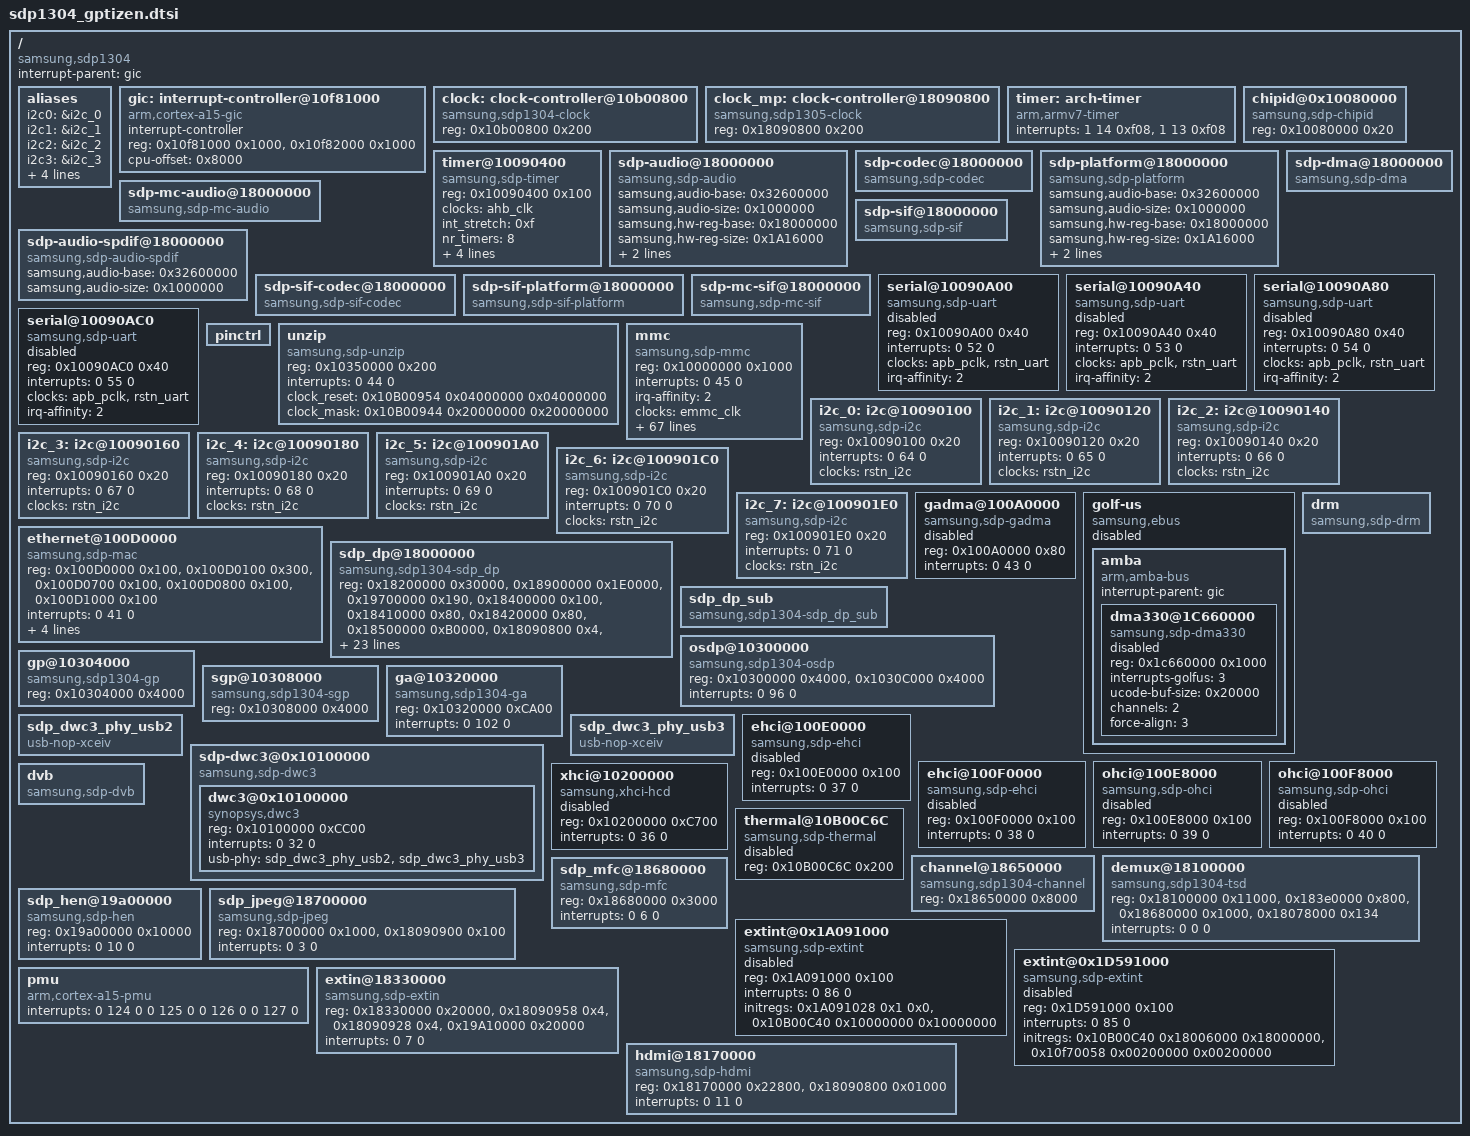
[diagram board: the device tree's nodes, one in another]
/*
 * Copyright (C) 2013 Samsung Electronics Co.Ltd
 *
 * This program is free software; you can redistribute it and/or modify
 * it under the terms of the GNU General Public License version 2 as
 * published by the Free Software Foundation.
 */

#include "sdp.dtsi"
#include "sdp1304-clocks.dtsi"
#include "sdp1304-pinctrl.dtsi"

/ {
	compatible = "samsung,sdp1304";

	interrupt-parent = <&gic>;

	aliases {
		i2c0 = &i2c_0;
		i2c1 = &i2c_1;
		i2c2 = &i2c_2;
		i2c3 = &i2c_3;
		i2c4 = &i2c_4;
		i2c5 = &i2c_5;
		i2c6 = &i2c_6;
		i2c7 = &i2c_7;
	};

	gic: interrupt-controller@10f81000 {
		compatible = "arm,cortex-a15-gic";
		interrupt-controller;
		#interrupt-cells = <3>;
		reg = <0x10f81000 0x1000>, <0x10f82000 0x1000>;
		cpu-offset = <0x8000>;
	};

	clock: clock-controller@10b00800 {
		compatible = "samsung,sdp1304-clock";
		reg = <0x10b00800 0x200>;
	};

	clock_mp: clock-controller@18090800 {
		compatible = "samsung,sdp1305-clock";
		reg = <0x18090800 0x200>;
	};

	timer: arch-timer {
		compatible = "arm,armv7-timer";
		interrupts = <1 14 0xf08>,
					 <1 13 0xf08>;
	};

	chipid@0x10080000 {
		compatible = "samsung,sdp-chipid";
		reg = <0x10080000 0x20>;
	};

	timer@10090400 {
		compatible = "samsung,sdp-timer";
		reg = <0x10090400 0x100>;
        clocks = <&ahb_clk>;
		clock-names = "ahb_clk";
		int_stretch = <0xf>;
		nr_timers = <8>;
		interrupts = <0 63 0>, <0 62 0>, <0 61 0>, <0 60 0>,
			<0 59 0>, <0 58 0>, <0 57 0>, <0 56 0>;
		clocksource_id = <0>;
		clockevent_id = <1>;
//		localtimer_ids = <4>, <5>, <6>, <7>;
	};


	sdp-audio@18000000 {
		compatible = "samsung,sdp-audio";
		samsung,audio-base = <0x32600000>;
		samsung,audio-size = <0x1000000>;
		samsung,hw-reg-base = <0x18000000>;
		samsung,hw-reg-size = <0x1A16000>;
		samsung,audio-aio-irq = <0x21>;
		samsung,audio-ae-irq = <0x22>;
	};

	sdp-codec@18000000  {
		compatible = "samsung,sdp-codec";
	};

	sdp-platform@18000000  {
		compatible = "samsung,sdp-platform";
		samsung,audio-base = <0x32600000>;
		samsung,audio-size = <0x1000000>;
		samsung,hw-reg-base = <0x18000000>;
		samsung,hw-reg-size = <0x1A16000>;
		samsung,audio-aio-irq = <0x21>;
		samsung,audio-ae-irq = <0x22>;		
	};

	sdp-dma@18000000  {
		compatible = "samsung,sdp-dma";
	};	

		
	sdp-mc-audio@18000000  {
		compatible = "samsung,sdp-mc-audio";
	};

	sdp-audio-spdif@18000000  {
		compatible = "samsung,sdp-audio-spdif";
		samsung,audio-base = <0x32600000>;
		samsung,audio-size = <0x1000000>;
	};

	sdp-sif@18000000  {
		compatible = "samsung,sdp-sif";
	};

	/*ALSA SIF*/
	sdp-sif-codec@18000000  {
		compatible = "samsung,sdp-sif-codec";
	};

	sdp-sif-platform@18000000  {
		compatible = "samsung,sdp-sif-platform";
	};

		
	sdp-mc-sif@18000000  {
		compatible = "samsung,sdp-mc-sif";
	};




	serial@10090A00 {
		compatible = "samsung,sdp-uart";
		reg = <0x10090A00 0x40>;
		interrupts = <0 52 0>;
		clocks = <&apb_pclk>, <&rstn_uart>;
		clock-names = "apb_pclk", "rstn_uart";
		irq-affinity = <2>;
		status = "disabled";
	};

	serial@10090A40 {
		compatible = "samsung,sdp-uart";
		reg = <0x10090A40 0x40>;
		interrupts = <0 53 0>;
		clocks = <&apb_pclk>, <&rstn_uart>;
		clock-names = "apb_pclk", "rstn_uart";
		irq-affinity = <2>;
		status = "disabled";
	};

	serial@10090A80 {
		compatible = "samsung,sdp-uart";
		reg = <0x10090A80 0x40>;
		interrupts = <0 54 0>;
		clocks = <&apb_pclk>, <&rstn_uart>;
		clock-names = "apb_pclk", "rstn_uart";
		irq-affinity = <2>;
		status = "disabled";
	};

	serial@10090AC0 {
		compatible = "samsung,sdp-uart";
		reg = <0x10090AC0 0x40>;
		interrupts = <0 55 0>;
		clocks = <&apb_pclk>, <&rstn_uart>;
		clock-names = "apb_pclk", "rstn_uart";
		irq-affinity = <2>;
		status = "disabled";
	};

	pinctrl{
		status = "okay";
	};

	unzip {
		compatible = "samsung,sdp-unzip";
		reg = <0x10350000 0x200>;
		interrupts = < 0 44 0 >;
		clock_reset = <0x10B00954 0x04000000 0x04000000>; 
		clock_mask = <0x10B00944 0x20000000 0x20000000>;
	};

	mmc {
		compatible = "samsung,sdp-mmc";
		reg = <0x10000000 0x1000>;
		interrupts = <0 45 0>;
		irq-affinity = <2>;
		clocks = <&emmc_clk>;
		clock-names = "emmc_clk";
		fifo-depth = <0x80>;
		min-max-clock = <400000 200000000>;
		initregs =	<0x10088014 0x0000000C 0x0000000C>,/* 33bit Accesss setting */
					<0x10B0092C 0x07FF07FF 0x00000101>,/* drv bypass, sam 0x101 delay */
					<0x10B00930 0x000002FF 0x000001E0>;/* sam buffer delay max, drv buffer delay min */

//		restoreregs =	<0x10B0092C 0x7FFF7FFF>;

		/* eMMC Sampling Clock Delay Selection. 1.25ns ~ 5ns for HS200 */
		tuning_set_size = <2>;
        tuning_sam =    <0x10B0092C 0x000007FF 0x00000100>, <0x10B00930 0x000001E0 0x00000000>,
                        <0x10B0092C 0x000007FF 0x00000100>, <0x10B00930 0x000001E0 0x000001E0>,
                        <0x10B0092C 0x000007FF 0x00000101>, <0x10B00930 0x000001E0 0x00000000>,
                        <0x10B0092C 0x000007FF 0x00000101>, <0x10B00930 0x000001E0 0x000001E0>,
                        <0x10B0092C 0x000007FF 0x00000102>, <0x10B00930 0x000001E0 0x00000000>,
                        <0x10B0092C 0x000007FF 0x00000102>, <0x10B00930 0x000001E0 0x000001E0>,
                        <0x10B0092C 0x000007FF 0x00000103>, <0x10B00930 0x000001E0 0x00000000>,
                        <0x10B0092C 0x000007FF 0x00000103>, <0x10B00930 0x000001E0 0x000001E0>,
                        <0x10B0092C 0x000007FF 0x00000200>, <0x10B00930 0x000001E0 0x00000000>,
                        <0x10B0092C 0x000007FF 0x00000200>, <0x10B00930 0x000001E0 0x000001E0>,
                        <0x10B0092C 0x000007FF 0x00000204>, <0x10B00930 0x000001E0 0x00000000>,
                        <0x10B0092C 0x000007FF 0x00000204>, <0x10B00930 0x000001E0 0x000001E0>,
                        <0x10B0092C 0x000007FF 0x00000208>, <0x10B00930 0x000001E0 0x00000000>,
                        <0x10B0092C 0x000007FF 0x00000208>, <0x10B00930 0x000001E0 0x000001E0>,
                        <0x10B0092C 0x000007FF 0x0000020C>, <0x10B00930 0x000001E0 0x00000000>,
                        <0x10B0092C 0x000007FF 0x0000020C>, <0x10B00930 0x000001E0 0x000001E0>,
                        <0x10B0092C 0x000007FF 0x00000300>, <0x10B00930 0x000001E0 0x00000000>,
                        <0x10B0092C 0x000007FF 0x00000300>, <0x10B00930 0x000001E0 0x000001E0>,
                        <0x10B0092C 0x000007FF 0x00000310>, <0x10B00930 0x000001E0 0x00000000>,
                        <0x10B0092C 0x000007FF 0x00000310>, <0x10B00930 0x000001E0 0x000001E0>,
                        <0x10B0092C 0x000007FF 0x00000320>, <0x10B00930 0x000001E0 0x00000000>,
                        <0x10B0092C 0x000007FF 0x00000320>, <0x10B00930 0x000001E0 0x000001E0>,
                        <0x10B0092C 0x000007FF 0x00000330>, <0x10B00930 0x000001E0 0x00000000>,
                        <0x10B0092C 0x000007FF 0x00000330>, <0x10B00930 0x000001E0 0x000001E0>;
                        //<0x10B0092C 0x000007FF 0x00000400>, <0x10B00930 0x000001E0 0x00000000>,
                        //<0x10B0092C 0x000007FF 0x00000400>, <0x10B00930 0x000001E0 0x000001E0>,
                        //<0x10B0092C 0x000007FF 0x00000410>, <0x10B00930 0x000001E0 0x00000000>,
                        //<0x10B0092C 0x000007FF 0x00000410>, <0x10B00930 0x000001E0 0x000001E0>,
                        //<0x10B0092C 0x000007FF 0x00000420>, <0x10B00930 0x000001E0 0x00000000>,
                        //<0x10B0092C 0x000007FF 0x00000420>, <0x10B00930 0x000001E0 0x000001E0>,
                        //<0x10B0092C 0x000007FF 0x00000430>, <0x10B00930 0x000001E0 0x00000000>,
                        //<0x10B0092C 0x000007FF 0x00000430>, <0x10B00930 0x000001E0 0x000001E0>;
                        //<0x10B0092C 0x000007FF 0x00000500>, <0x10B00930 0x000001E0 0x00000000>,
                        //<0x10B0092C 0x000007FF 0x00000500>, <0x10B00930 0x000001E0 0x000001E0>,
                        //<0x10B0092C 0x000007FF 0x00000510>, <0x10B00930 0x000001E0 0x00000000>,
                        //<0x10B0092C 0x000007FF 0x00000510>, <0x10B00930 0x000001E0 0x000001E0>,
                        //<0x10B0092C 0x000007FF 0x00000520>, <0x10B00930 0x000001E0 0x00000000>,
                        //<0x10B0092C 0x000007FF 0x00000520>, <0x10B00930 0x000001E0 0x000001E0>,
                        //<0x10B0092C 0x000007FF 0x00000530>, <0x10B00930 0x000001E0 0x00000000>,
                        //<0x10B0092C 0x000007FF 0x00000530>, <0x10B00930 0x000001E0 0x000001E0>;

        tuning_sam_hs200_default = <0x10B0092C 0x000007FF 0x00000100>, <0x10B00930 0x000001E0 0x00000000>;/* HS200 sampling defalut */
        tuning_drv_hs200_default = <0x10B0092C 0x07FF0000 0x02080000>, <0x10B00930 0x0000000F 0x0000000F>, <0x10B00804 0xFFFFFFFF 0x0030FA01>, <0x10B00908 0x0000000F 0x00000005>;/* HS200 driving defalut HS200 166Mhz */

		bus-width = <0x8>;
//		force-pio-mode;
		hw-reset;

		/* Host Caps */
		non-removable;
//		bus-width-test;
		highspeed;
//		sdr104;
		ddr50;
//		hs200;
//		hs200-tuning;
	};

	i2c_0: i2c@10090100 {
		#address-cells = <1>;
		#size-cells = <0>;
		compatible = "samsung,sdp-i2c";
		reg = <0x10090100 0x20>;
		interrupts = <0 64 0>;
		clocks = <&rstn_i2c>;
		clock-names = "rstn_i2c";
	};

	i2c_1: i2c@10090120 {
		#address-cells = <1>;
		#size-cells = <0>;
		compatible = "samsung,sdp-i2c";
		reg = <0x10090120 0x20>;
		interrupts = <0 65 0>;
		clocks = <&rstn_i2c>;
		clock-names = "rstn_i2c";
	};

	i2c_2: i2c@10090140 {
		#address-cells = <1>;
		#size-cells = <0>;
		compatible = "samsung,sdp-i2c";
		reg = <0x10090140 0x20>;
		interrupts = <0 66 0>;
		clocks = <&rstn_i2c>;
		clock-names = "rstn_i2c";
	};

	i2c_3: i2c@10090160 {
		#address-cells = <1>;
		#size-cells = <0>;
		compatible = "samsung,sdp-i2c";
		reg = <0x10090160 0x20>;
		interrupts = <0 67 0>;
		clocks = <&rstn_i2c>;
		clock-names = "rstn_i2c";
	};

	i2c_4: i2c@10090180 {
		#address-cells = <1>;
		#size-cells = <0>;
		compatible = "samsung,sdp-i2c";
		reg = <0x10090180 0x20>;
		interrupts = <0 68 0>;
		clocks = <&rstn_i2c>;
		clock-names = "rstn_i2c";
	};

	i2c_5: i2c@100901A0 {
		#address-cells = <1>;
		#size-cells = <0>;
		compatible = "samsung,sdp-i2c";
		reg = <0x100901A0 0x20>;
		interrupts = <0 69 0>;
		clocks = <&rstn_i2c>;
		clock-names = "rstn_i2c";
	};

	i2c_6: i2c@100901C0 {
		#address-cells = <1>;
		#size-cells = <0>;
		compatible = "samsung,sdp-i2c";
		reg = <0x100901C0 0x20>;
		interrupts = <0 70 0>;
		clocks = <&rstn_i2c>;
		clock-names = "rstn_i2c";
	};

	i2c_7: i2c@100901E0 {
		#address-cells = <1>;
		#size-cells = <0>;
		compatible = "samsung,sdp-i2c";
		reg = <0x100901E0 0x20>;
		interrupts = <0 71 0>;
		clocks = <&rstn_i2c>;
		clock-names = "rstn_i2c";
	};

	gadma@100A0000 {
		compatible = "samsung,sdp-gadma";
		reg = <0x100A0000 0x80>;
		interrupts = <0 43 0>;
		status = "disabled";
	};


	golf-us {
		status = "disabled";

		#address-cells = <1>;
		#size-cells = <1>;
		compatible = "samsung,ebus", "simple-bus";
		ranges;

		amba {
			#address-cells = <1>;
			#size-cells = <1>;
			compatible = "arm,amba-bus";
			interrupt-parent = <&gic>;
			ranges;

			dma330@1C660000 {
				status = "disabled";
				compatible = "samsung,sdp-dma330", "arm,primecell";
				reg = <0x1c660000 0x1000>;
				interrupts-golfus = <3>;

				ucode-buf-size = <0x20000>;/*128kb*/
				channels = <2>;
				force-align = <3>;/* 2^n */
			};
		};
	};

	ethernet@100D0000 {
		compatible = "samsung,sdp-mac";
		reg = <0x100D0000 0x100>,
			<0x100D0100 0x300>,
			<0x100D0700 0x100>,
			<0x100D0800 0x100>,
			<0x100D1000 0x100>;
		interrupts = <0 41 0>;
		pad_ctrl_reg = <0x10088008 0x100 0x100>;
		bus_width = <64>;
		phy_mask = <0>;
		napi_weight = <128>;
	};

	sdp_dp@18000000 {
		compatible = "samsung,sdp1304-sdp_dp";
		reg =	<0x18200000 0x30000>,	/* POST */
			<0x18900000 0x1E0000>,	/* NORMAL */
			<0x19700000 0x190>,	/* ROTATION */
			<0x18400000 0x100>,	/* BUS */
			<0x18410000 0x80>,	/* XMIF-A */
			<0x18420000 0x80>,	/* XMIF-B */
			<0x18500000 0xB0000>,	/* BUS-MON. */
			<0x18090800 0x4>,	/* VID_LVDSRX_PMS */
			<0x18090834 0x4>,	/* REG_VID_PLL_K */
			<0x18090930 0x4>,	/* REG_DP_CLK_MUXSEL8 */
			<0x180908b0 0x4>,	/* VID_CLK_MUX_SEL_LVDSTX2 */
			<0x18090924 0x4>,	/* VID_CLK_MUX_SEL */
			<0x18090930 0x4>,	/* VID_CLK_MUX_SEL_PREIVEW */
			<0x18090934 0x4>,	/* VID_CLK_MUX_SEL_LVDSTX */
			<0x18090940 0x4>,	/* VID_LVDS_CLK_MUX_SEL */
			<0x18090c98 0x4>,	/* VID_LVDSRX_CLK_RESET */
			<0x18090c58 0x4>,	/* VID_LVDSTX_CLK_RESET */
			<0x18090c68 0x4>,	/* VID_LVDSTX_CLKCTRL0 */
			<0x18090c80 0x4>,	/* VID_LVDSTX_CLKCTRL1 */
			<0x18090d0c 0x4>,	/* VID_LVDSRX_CLKCTRL2 */
			<0x18090d3c 0x4>,	/* VID_LVDSRX_CLKCTRL3 */
			<0x18110080 0x4>,	/* REG_DP_TSDSTC */
			<0x18090c78 0x4>,	/* REG_DP_LVDSRX0_RESET */
			<0x18090c7c 0x4>;	/* REG_DP_LVDSRX1_RESET */
			
		interrupts 		= <0 4 0>;
		samsung,dp0 		= <0 0x33D00000 0x2AC0000>;	/* 42.75 Mbyte*/
		samsung,dp1 		= <0 0x24C80000 0x241EB86>;	/* 36.12 Mbyte*/	
		samsung,dp2 		= <0 0x367C0000 0xE20000>;	/* 14.125 Mbyte*/
		samsung,dp3 		= <0 0x2709EB85 0xB47AE1>;	/* 11.28 Mbyte*/	
		samsung,rm_cap_wry 	= <0 0x82800000 0xC5000>;	
		samsung,rm_cap_wrc 	= <0 0x828C5000 0xC5000>;
		samsung,main_cap_wry 	= <0 0x8298A000 0x1FB000>;	
		samsung,main_cap_wrc	= <0 0x82B85000 0xFE000>;
		samsung,sub_cap_wry 	= <0 0x82C83000 0x1FB000>;	
		samsung,sub_cap_wrc 	= <0 0x82E7E000 0xFE000>;
		samsung,dp_enc_buf 	= <0 0x31880000 0x680000>;

		clocks      = <&disp_pclk_nr>,  <&disp_pclk_dcar>,  <&disp_pclk_ipc>,  <&disp_pclk_ucar>,   <&dp_scl_osc_clk>,   <&dp_scl_sub_clk>,   <&dp_scl_pclk>;
		clock-names = "disp_pclk_nr", "disp_pclk_dcar", "disp_pclk_ipc", "disp_pclk_ucar", "dp_scl_osc_clk", "dp_scl_sub_clk", "dp_scl_pclk";
	};

	sdp_dp_sub {
		compatible = "samsung,sdp1304-sdp_dp_sub";
	};

        drm {
                compatible = "samsung,sdp-drm";
        };

        osdp@10300000 {
                compatible = "samsung,sdp1304-osdp";
                reg =	<0x10300000 0x4000>, /* OSD Plane REGs */
			<0x1030C000 0x4000>; /* Mixer REGs */
                interrupts = <0 96 0>;
        };

        gp@10304000 {
                compatible = "samsung,sdp1304-gp";
                reg = <0x10304000 0x4000>;
        };

        sgp@10308000 {
                compatible = "samsung,sdp1304-sgp";
                reg = <0x10308000 0x4000>;
        };

        ga@10320000 {
                compatible = "samsung,sdp1304-ga";
                reg = <0x10320000 0xCA00>;
                interrupts = <0 102 0>;
        };
	sdp_dwc3_phy_usb2: sdp_dwc3_phy_usb2 {
		compatible = "usb-nop-xceiv";
	};
	sdp_dwc3_phy_usb3: sdp_dwc3_phy_usb3 {
		compatible = "usb-nop-xceiv";
	};
	sdp-dwc3@0x10100000 {
		compatible = "samsung,sdp-dwc3";
		#address-cells = <1>;
		#size-cells = <1>;
		ranges;
		dwc3@0x10100000 {
			compatible = "synopsys,dwc3";
			reg = <0x10100000 0xCC00>;
			interrupts = <0 32 0>;
			usb-phy = <&sdp_dwc3_phy_usb2>, <&sdp_dwc3_phy_usb3>;
		};
	};

	ehci@100E0000 {
		compatible = "samsung,sdp-ehci", "usb-ehci";
		reg = <0x100E0000 0x100>;
		interrupts = <0 37 0>;
		status = "disabled";
	};

	ehci@100F0000 {
		compatible = "samsung,sdp-ehci", "usb-ehci";
		reg = <0x100F0000 0x100>;
		interrupts = <0 38 0>;
		status = "disabled";
	};

	ohci@100E8000 {
		compatible = "samsung,sdp-ohci", "usb-ohci";
		reg = <0x100E8000 0x100>;
		interrupts = <0 39 0>;
		status = "disabled";
	};

	ohci@100F8000 {
		compatible = "samsung,sdp-ohci", "usb-ohci";
		reg = <0x100F8000 0x100>;
		interrupts = <0 40 0>;
		status = "disabled";
	};

	xhci@10200000 {
		compatible = "samsung,xhci-hcd", "usb-xhci";
		reg = <0x10200000 0xC700>;
		interrupts = <0 36 0>;
		status = "disabled";
	};

	thermal@10B00C6C {
		compatible = "samsung,sdp-thermal";
		reg = <0x10B00C6C 0x200>;
		status = "disabled";
	};

	dvb {
		compatible = "samsung,sdp-dvb";
	};

	channel@18650000 {
		compatible = "samsung,sdp1304-channel";
		reg = <0x18650000 0x8000>;
	};

	demux@18100000 {
		compatible = "samsung,sdp1304-tsd";
                reg = <0x18100000 0x11000>, <0x183e0000 0x800>, <0x18680000 0x1000>,
			<0x18078000 0x134>;
                reg-names = "tsd", "se", "mfd", "ci";
		interrupts = <0 0 0>;
	};

	sdp_mfc@18680000 {
		compatible = "samsung,sdp-mfc";
		reg = <0x18680000 0x3000>;
		interrupts = <0 6 0>;
	};

	sdp_hen@19a00000 {
		compatible = "samsung,sdp-hen";
		reg = <0x19a00000 0x10000>;
		interrupts = <0 10 0>;
	};

        sdp_jpeg@18700000 {
                compatible = "samsung,sdp-jpeg";
                reg = <0x18700000 0x1000>, <0x18090900 0x100>;
                interrupts = <0 3 0>;
        };
	
	extint@0x1A091000 {
		compatible = "samsung,sdp-extint";
		reg = <0x1A091000 0x100>;
		interrupts = <0 86 0>;
		initregs = <0x1A091028 0x1 0x0>,	/* STM off */
			<0x10B00C40 0x10000000 0x10000000>;		/* Externel Interrupt Enable */
		status = "disabled";
	};

	extint@0x1D591000 {
		compatible = "samsung,sdp-extint";
		reg = <0x1D591000 0x100>;
		interrupts = <0 85 0>;
		initregs = <0x10B00C40 0x18006000 0x18000000>,	/* Externel Interrupt Enable */
			<0x10f70058 0x00200000 0x00200000>;	/* GIC Polarity Invert */
		status = "disabled";
	};
	
	pmu	{
		compatible = "arm,cortex-a15-pmu";
		interrupts = <0 124 0
				0 125 0
				0 126 0
				0 127 0>;
	};
	extin@18330000 {
		compatible = "samsung,sdp-extin";
		reg = <0x18330000 0x20000>, <0x18090958 0x4>, <0x18090928 0x4>, <0x19A10000 0x20000>;
		reg-names = "avd-reg", "reg-mp0_sw_rst", "reg-mux_sel6", "afe-reg";
		interrupts = <0 7 0>;
	};


	hdmi@18170000 {
		compatible = "samsung,sdp-hdmi";
		reg = <0x18170000 0x22800>, <0x18090800 0x01000>;
		reg-names = "hdmi-reg", "hdmi-clk";
		interrupts = <0 11 0>;
	};

};
